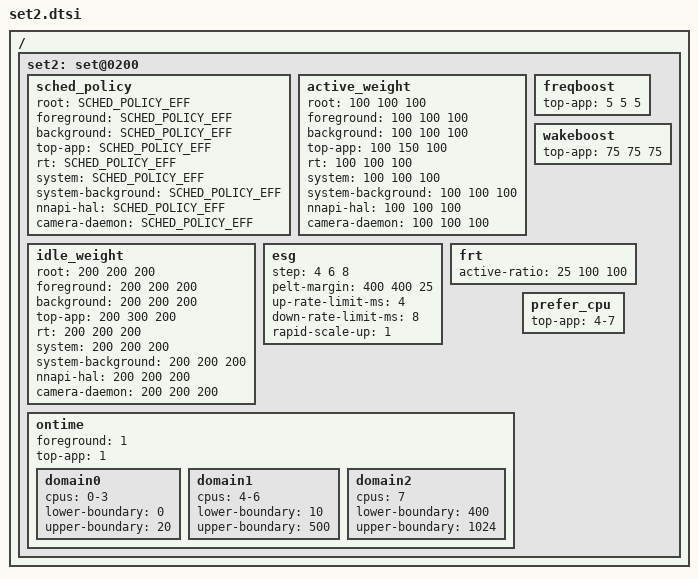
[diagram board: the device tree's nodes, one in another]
/ {
	/* performance mode - default */
	set2: set@0200 {
		/* schedudling policy */
		sched_policy {
			root			= <SCHED_POLICY_EFF>;
			foreground 		= <SCHED_POLICY_EFF>;
			background		= <SCHED_POLICY_EFF>;
			top-app			= <SCHED_POLICY_EFF>;
			rt			= <SCHED_POLICY_EFF>;
			system			= <SCHED_POLICY_EFF>;
			system-background	= <SCHED_POLICY_EFF>;
			nnapi-hal		= <SCHED_POLICY_EFF>;
			camera-daemon		= <SCHED_POLICY_EFF>;
		};

		/* weight (%) applied to active cpu's efficiency */
		active_weight {			/* LIT MED BIG */
			root			= <100 100 100>;
			foreground		= <100 100 100>;
			background		= <100 100 100>;
			top-app			= <100 150 100>;
			rt			= <100 100 100>;
			system			= <100 100 100>;
			system-background	= <100 100 100>;
			nnapi-hal		= <100 100 100>;
			camera-daemon		= <100 100 100>;
		};

		/* weight (%) applied to idle cpu's efficiency */
		idle_weight {			/* LIT MED BIG */
			root			= <200 200 200>;
			foreground		= <200 200 200>;
			background		= <200 200 200>;
			top-app			= <200 300 200>;
			rt			= <200 200 200>;
			system			= <200 200 200>;
			system-background	= <200 200 200>;
			nnapi-hal		= <200 200 200>;
			camera-daemon		= <200 200 200>;
		};

		/* Boosting margin applied to frequency selection */
		freqboost {			/* LIT MED BIG */
			top-app			= <  5   5   5>;
		};

		/* Boosting margin for waking up task */
		wakeboost {			/* LIT MED BIG */
			top-app			= < 75  75  75>;
		};

		/* gov-data used by ESG */
		esg {				/* LIT MED BIG */
			step			= <  4   6   8>;
			pelt-margin		= <400 400  25>;

			up-rate-limit-ms	= <4>;
			down-rate-limit-ms	= <8>;
			rapid-scale-up		= <1>;
		};

		frt {	   	     		/* LIT MED BIG */
			active-ratio		= < 25 100 100>;
		};

		/* Ontime Migration */
		ontime {
			foreground 	= <1>;
			top-app		= <1>;

			domain0 {
				cpus = "0-3";
				lower-boundary = <0>;
				upper-boundary = <20>;
			};
			domain1 {
				cpus = "4-6";
				lower-boundary = <10>;
				upper-boundary = <500>;
			};
			domain2 {
				cpus = "7";
				lower-boundary = <400>;
				upper-boundary = <1024>;
			};
		};

		prefer_cpu {
			top-app = "4-7";
		};
	};
};
